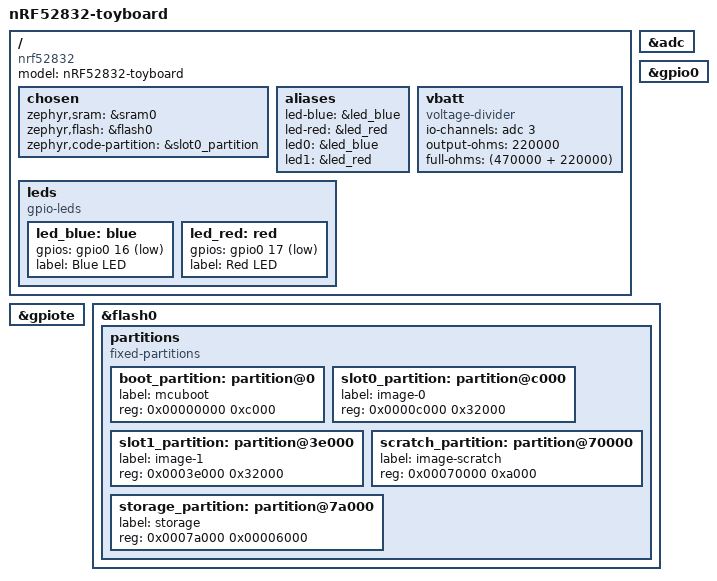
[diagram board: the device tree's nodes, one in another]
/*
 * SPDX-License-Identifier: Apache-2.0
 */

/dts-v1/;
#include <nordic/nrf52832_qfaa.dtsi>

/ {
	model = "nRF52832-toyboard";
	compatible = "nrf52832";

	chosen {
		zephyr,sram = &sram0;
		zephyr,flash = &flash0;
		zephyr,code-partition = &slot0_partition;
	};

	aliases {
		led-blue = &led_blue;
		led-red = &led_red;
		led0 = &led_blue;
		led1 = &led_red;
	};

	leds {
		compatible = "gpio-leds";
		led_blue: blue {
			gpios = <&gpio0 16 GPIO_ACTIVE_LOW>;
			label = "Blue LED";
		};
		led_red: red {
			gpios = <&gpio0 17 GPIO_ACTIVE_LOW>;
			label = "Red LED";
		};
	};

	vbatt {
		compatible = "voltage-divider";
		io-channels = <&adc 3>;
		output-ohms = <220000>;
		full-ohms = <(470000 + 220000)>;
	};
};

&adc {
	status = "okay";
};

&gpiote {
	status = "okay";
};

&gpio0 {
	status = "okay";
};

&flash0 {
	/*
	 * For more information, see:
	 * https://docs.zephyrproject.org/latest/guides/dts/legacy-macros.html#legacy-flash-partitions
	 */
	partitions {
		compatible = "fixed-partitions";
		#address-cells = <1>;
		#size-cells = <1>;

		boot_partition: partition@0 {
			label = "mcuboot";
			reg = <0x00000000 0xc000>;
		};
		slot0_partition: partition@c000 {
			label = "image-0";
			reg = <0x0000c000 0x32000>;
		};
		slot1_partition: partition@3e000 {
			label = "image-1";
			reg = <0x0003e000 0x32000>;
		};
		scratch_partition: partition@70000 {
			label = "image-scratch";
			reg = <0x00070000 0xa000>;
		};
		storage_partition: partition@7a000 {
			label = "storage";
			reg = <0x0007a000 0x00006000>;
		};
	};
};
